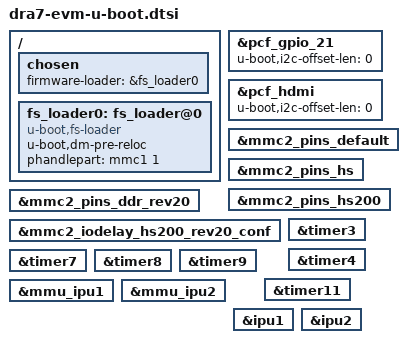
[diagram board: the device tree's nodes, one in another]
// SPDX-License-Identifier: GPL-2.0+
/*
 * Copyright (C) 2017 Texas Instruments Incorporated - http://www.ti.com/
 */

#include "omap5-u-boot.dtsi"

/ {
	chosen {
		firmware-loader = &fs_loader0;
	};

	fs_loader0: fs_loader@0 {
		u-boot,dm-pre-reloc;
		compatible = "u-boot,fs-loader";
		phandlepart = <&mmc1 1>;
	};
};

&pcf_gpio_21{
	u-boot,i2c-offset-len = <0>;
};

&pcf_hdmi{
	u-boot,i2c-offset-len = <0>;
};

&mmc2_pins_default {
	u-boot,dm-spl;
};

&mmc2_pins_hs {
	u-boot,dm-spl;
};

&mmc2_pins_ddr_rev20 {
	u-boot,dm-spl;
};

&mmc2_pins_hs200 {
	u-boot,dm-spl;
};

&mmc2_iodelay_hs200_rev20_conf {
	u-boot,dm-spl;
};

&timer3 {
	u-boot,dm-spl;
};

&timer4 {
	u-boot,dm-spl;
};

&timer7 {
	u-boot,dm-spl;
};

&timer8 {
	u-boot,dm-spl;
};

&timer9 {
	u-boot,dm-spl;
};

&timer11 {
	u-boot,dm-spl;
};

&mmu_ipu1 {
	u-boot,dm-spl;
};

&mmu_ipu2 {
	u-boot,dm-spl;
};

&ipu1 {
	status = "okay";
	u-boot,dm-spl;
};

&ipu2 {
	status = "okay";
	u-boot,dm-spl;
};
